# ioam3358 register map
Registers are 32-bit, access not given, no defined reset value unless marked. A register's access mark holds for its fields unless they carry their own. Addresses are absolute; registers are grouped by the start of their names; [hi:lo] are bit positions; {n}, {i} and the like mark numbered series; 'fields as' and 'values as' point back to an identical list.

## CM
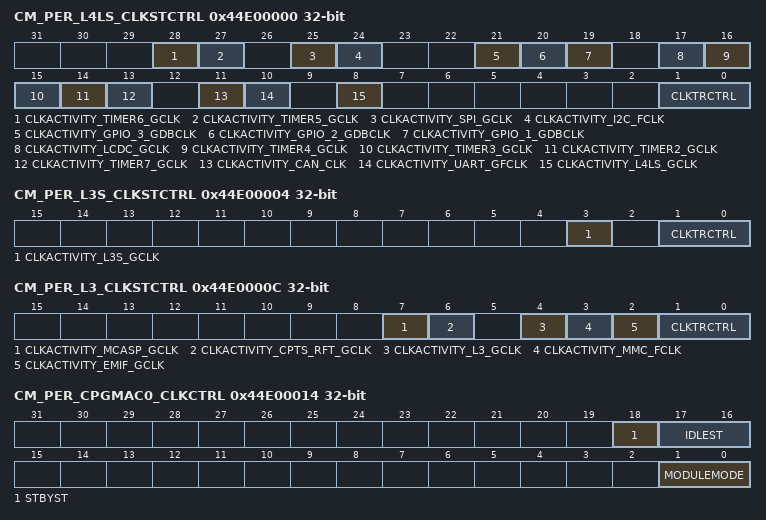
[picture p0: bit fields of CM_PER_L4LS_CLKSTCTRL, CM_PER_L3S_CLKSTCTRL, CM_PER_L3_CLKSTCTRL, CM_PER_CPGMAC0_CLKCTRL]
0x44E00000 CM_PER_L4LS_CLKSTCTRL
  [28] CLKACTIVITY_TIMER6_GCLK, [27] CLKACTIVITY_TIMER5_GCLK, [25] CLKACTIVITY_SPI_GCLK, [24] CLKACTIVITY_I2C_FCLK, [21] CLKACTIVITY_GPIO_3_GDBCLK, [20] CLKACTIVITY_GPIO_2_GDBCLK, [19] CLKACTIVITY_GPIO_1_GDBCLK, [17] CLKACTIVITY_LCDC_GCLK, [16] CLKACTIVITY_TIMER4_GCLK, [15] CLKACTIVITY_TIMER3_GCLK, [14] CLKACTIVITY_TIMER2_GCLK, [13] CLKACTIVITY_TIMER7_GCLK, [11] CLKACTIVITY_CAN_CLK, [10] CLKACTIVITY_UART_GFCLK, [8] CLKACTIVITY_L4LS_GCLK, [1:0] CLKTRCTRL
0x44E00004 CM_PER_L3S_CLKSTCTRL
  [3] CLKACTIVITY_L3S_GCLK, [1:0] CLKTRCTRL
0x44E0000C CM_PER_L3_CLKSTCTRL
  [7] CLKACTIVITY_MCASP_GCLK, [6] CLKACTIVITY_CPTS_RFT_GCLK, [4] CLKACTIVITY_L3_GCLK, [3] CLKACTIVITY_MMC_FCLK, [2] CLKACTIVITY_EMIF_GCLK, [1:0] CLKTRCTRL
0x44E00014 CM_PER_CPGMAC0_CLKCTRL
  [18] STBYST, [17:16] IDLEST, [1:0] MODULEMODE
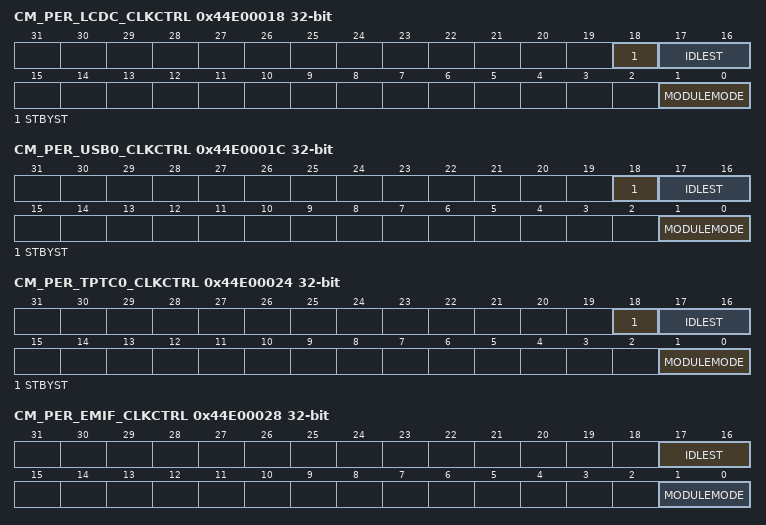
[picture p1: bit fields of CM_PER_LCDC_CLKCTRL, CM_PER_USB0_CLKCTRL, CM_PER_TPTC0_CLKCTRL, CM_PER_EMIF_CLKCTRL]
0x44E00018 CM_PER_LCDC_CLKCTRL
  [18] STBYST, [17:16] IDLEST, [1:0] MODULEMODE
0x44E0001C CM_PER_USB0_CLKCTRL
  [18] STBYST, [17:16] IDLEST, [1:0] MODULEMODE
0x44E00024 CM_PER_TPTC0_CLKCTRL
  [18] STBYST, [17:16] IDLEST, [1:0] MODULEMODE
0x44E00028 CM_PER_EMIF_CLKCTRL
  [17:16] IDLEST, [1:0] MODULEMODE
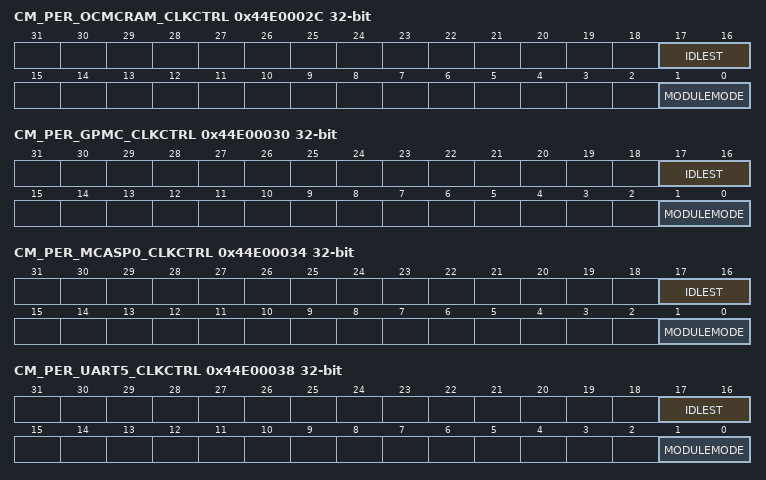
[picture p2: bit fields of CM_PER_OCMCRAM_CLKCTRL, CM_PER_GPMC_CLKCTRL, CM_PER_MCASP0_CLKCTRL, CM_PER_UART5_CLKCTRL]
0x44E0002C CM_PER_OCMCRAM_CLKCTRL
  [17:16] IDLEST, [1:0] MODULEMODE
0x44E00030 CM_PER_GPMC_CLKCTRL
  [17:16] IDLEST, [1:0] MODULEMODE
0x44E00034 CM_PER_MCASP0_CLKCTRL
  [17:16] IDLEST, [1:0] MODULEMODE
0x44E00038 CM_PER_UART5_CLKCTRL
  [17:16] IDLEST, [1:0] MODULEMODE
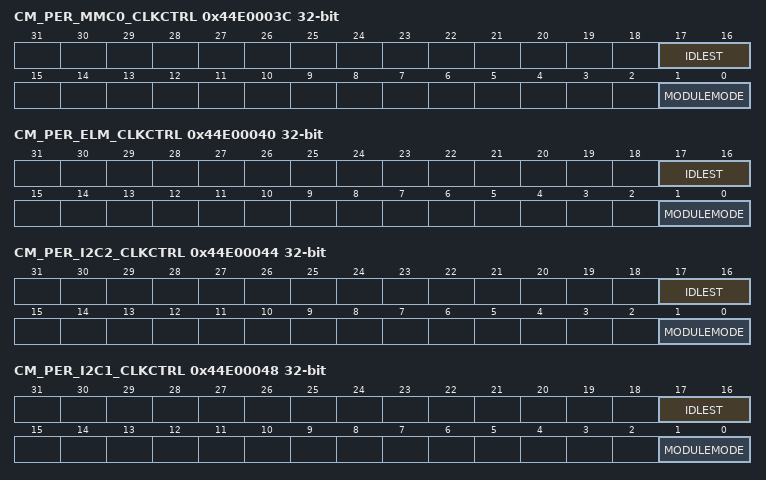
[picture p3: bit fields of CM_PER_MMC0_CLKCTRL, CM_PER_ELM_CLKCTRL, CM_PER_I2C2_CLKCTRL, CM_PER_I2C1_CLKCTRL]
0x44E0003C CM_PER_MMC0_CLKCTRL
  [17:16] IDLEST, [1:0] MODULEMODE
0x44E00040 CM_PER_ELM_CLKCTRL
  [17:16] IDLEST, [1:0] MODULEMODE
0x44E00044 CM_PER_I2C2_CLKCTRL
  [17:16] IDLEST, [1:0] MODULEMODE
0x44E00048 CM_PER_I2C1_CLKCTRL
  [17:16] IDLEST, [1:0] MODULEMODE
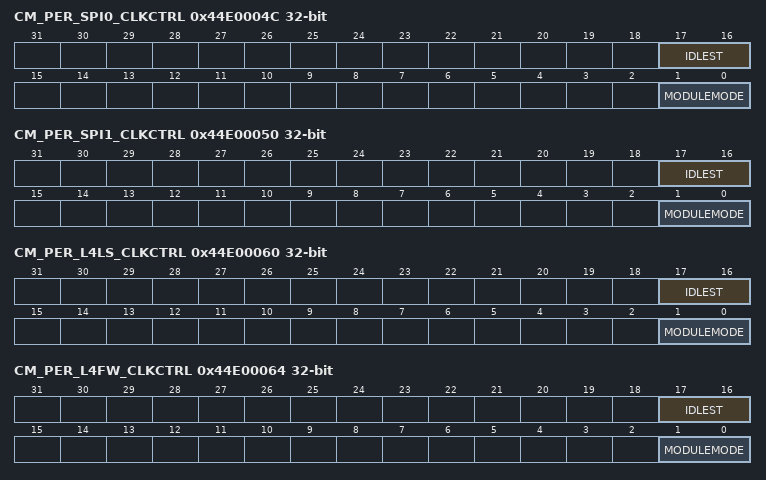
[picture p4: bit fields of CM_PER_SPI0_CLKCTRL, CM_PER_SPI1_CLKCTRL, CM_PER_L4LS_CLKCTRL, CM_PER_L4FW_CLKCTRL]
0x44E0004C CM_PER_SPI0_CLKCTRL
  [17:16] IDLEST, [1:0] MODULEMODE
0x44E00050 CM_PER_SPI1_CLKCTRL
  [17:16] IDLEST, [1:0] MODULEMODE
0x44E00060 CM_PER_L4LS_CLKCTRL
  [17:16] IDLEST, [1:0] MODULEMODE
0x44E00064 CM_PER_L4FW_CLKCTRL
  [17:16] IDLEST, [1:0] MODULEMODE
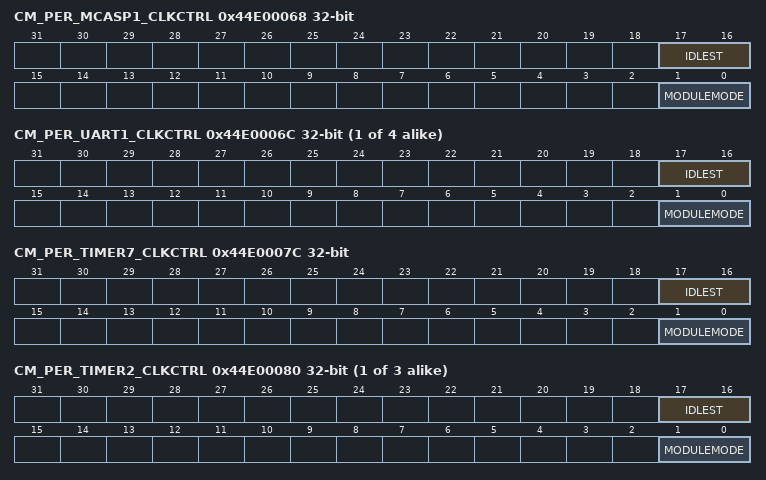
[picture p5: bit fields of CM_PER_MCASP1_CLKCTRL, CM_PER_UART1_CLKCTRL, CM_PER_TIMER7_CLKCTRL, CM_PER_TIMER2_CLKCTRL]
0x44E00068 CM_PER_MCASP1_CLKCTRL
  [17:16] IDLEST, [1:0] MODULEMODE
{0x44E00068+4i} CM_PER_UART{i}_CLKCTRL (i=1..4)
  [17:16] IDLEST, [1:0] MODULEMODE
0x44E0007C CM_PER_TIMER7_CLKCTRL
  [17:16] IDLEST, [1:0] MODULEMODE
{0x44E00078+4i} CM_PER_TIMER{i}_CLKCTRL (i=2..4)
  [17:16] IDLEST, [1:0] MODULEMODE
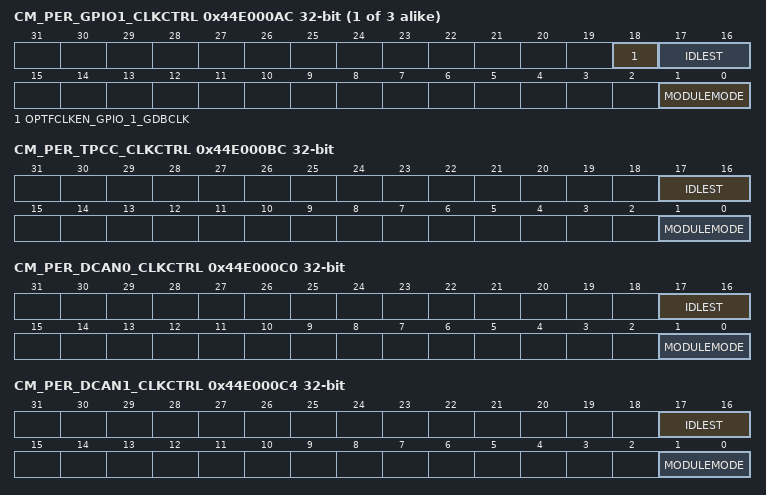
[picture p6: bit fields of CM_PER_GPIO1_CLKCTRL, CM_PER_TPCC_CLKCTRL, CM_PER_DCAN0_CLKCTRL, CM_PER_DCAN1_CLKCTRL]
{0x44E000A8+4i} CM_PER_GPIO{i}_CLKCTRL (i=1..3)
  [18] OPTFCLKEN_GPIO_{i}_GDBCLK, [17:16] IDLEST, [1:0] MODULEMODE
0x44E000BC CM_PER_TPCC_CLKCTRL
  [17:16] IDLEST, [1:0] MODULEMODE
0x44E000C0 CM_PER_DCAN0_CLKCTRL
  [17:16] IDLEST, [1:0] MODULEMODE
0x44E000C4 CM_PER_DCAN1_CLKCTRL
  [17:16] IDLEST, [1:0] MODULEMODE
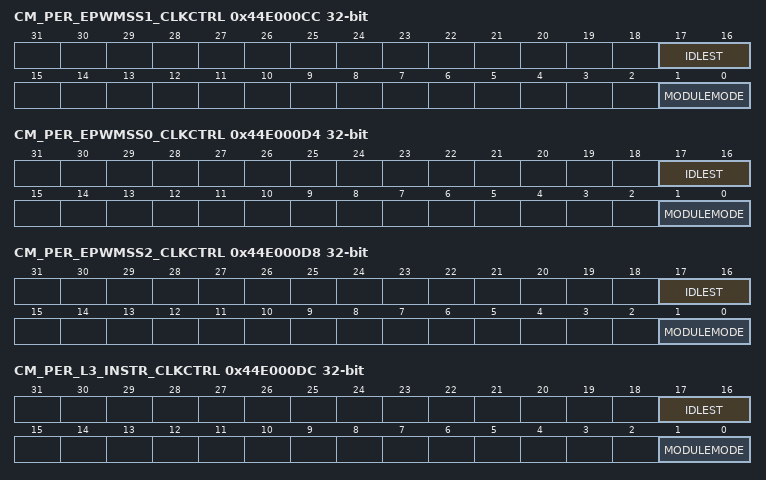
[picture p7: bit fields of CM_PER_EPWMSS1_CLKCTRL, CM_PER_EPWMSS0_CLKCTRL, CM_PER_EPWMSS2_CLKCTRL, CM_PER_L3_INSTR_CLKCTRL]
0x44E000CC CM_PER_EPWMSS1_CLKCTRL
  [17:16] IDLEST, [1:0] MODULEMODE
0x44E000D4 CM_PER_EPWMSS0_CLKCTRL
  [17:16] IDLEST, [1:0] MODULEMODE
0x44E000D8 CM_PER_EPWMSS2_CLKCTRL
  [17:16] IDLEST, [1:0] MODULEMODE
0x44E000DC CM_PER_L3_INSTR_CLKCTRL
  [17:16] IDLEST, [1:0] MODULEMODE
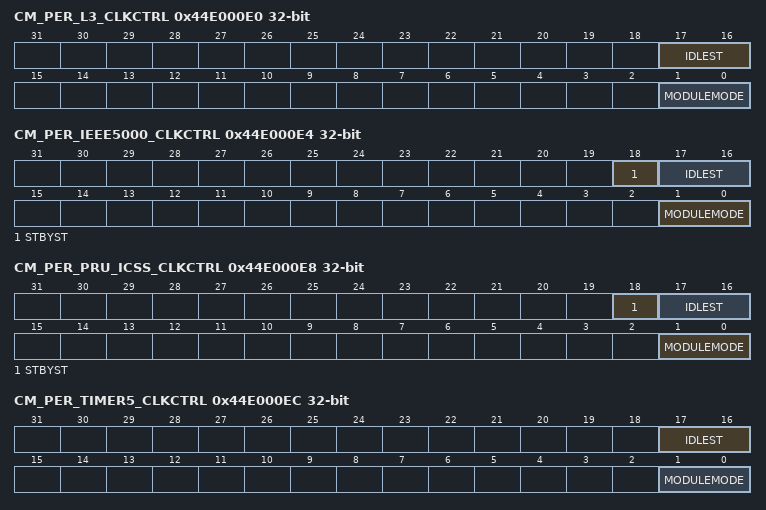
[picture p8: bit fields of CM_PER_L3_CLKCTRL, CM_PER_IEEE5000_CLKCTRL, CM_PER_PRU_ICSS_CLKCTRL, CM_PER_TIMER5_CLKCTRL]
0x44E000E0 CM_PER_L3_CLKCTRL
  [17:16] IDLEST, [1:0] MODULEMODE
0x44E000E4 CM_PER_IEEE5000_CLKCTRL
  [18] STBYST, [17:16] IDLEST, [1:0] MODULEMODE
0x44E000E8 CM_PER_PRU_ICSS_CLKCTRL
  [18] STBYST, [17:16] IDLEST, [1:0] MODULEMODE
0x44E000EC CM_PER_TIMER5_CLKCTRL
  [17:16] IDLEST, [1:0] MODULEMODE
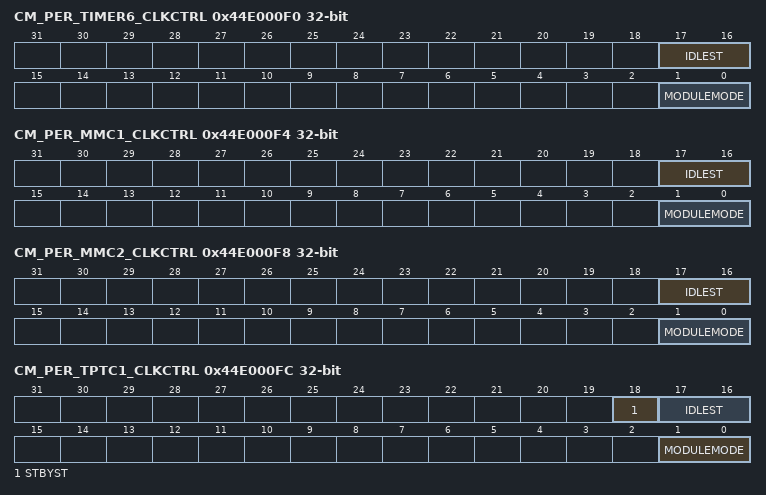
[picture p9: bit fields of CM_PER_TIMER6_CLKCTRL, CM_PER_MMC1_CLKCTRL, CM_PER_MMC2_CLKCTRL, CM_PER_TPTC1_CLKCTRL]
0x44E000F0 CM_PER_TIMER6_CLKCTRL
  [17:16] IDLEST, [1:0] MODULEMODE
0x44E000F4 CM_PER_MMC1_CLKCTRL
  [17:16] IDLEST, [1:0] MODULEMODE
0x44E000F8 CM_PER_MMC2_CLKCTRL
  [17:16] IDLEST, [1:0] MODULEMODE
0x44E000FC CM_PER_TPTC1_CLKCTRL
  [18] STBYST, [17:16] IDLEST, [1:0] MODULEMODE
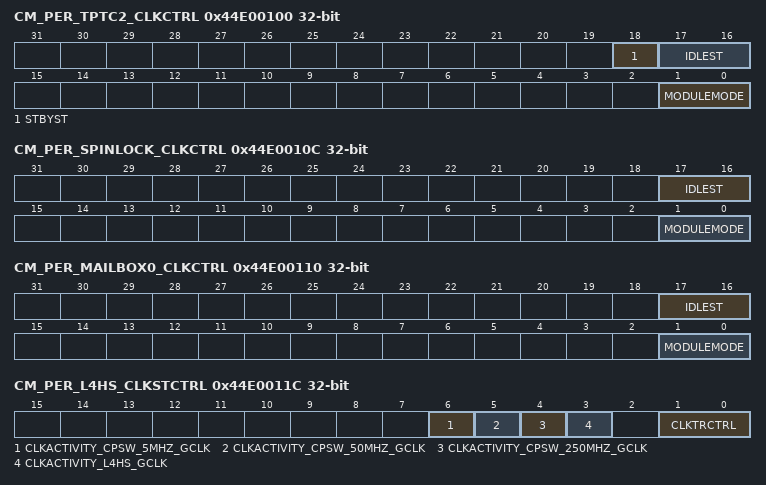
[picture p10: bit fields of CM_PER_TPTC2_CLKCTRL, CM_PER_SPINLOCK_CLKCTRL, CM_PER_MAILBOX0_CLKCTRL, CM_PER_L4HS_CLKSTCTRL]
0x44E00100 CM_PER_TPTC2_CLKCTRL
  [18] STBYST, [17:16] IDLEST, [1:0] MODULEMODE
0x44E0010C CM_PER_SPINLOCK_CLKCTRL
  [17:16] IDLEST, [1:0] MODULEMODE
0x44E00110 CM_PER_MAILBOX0_CLKCTRL
  [17:16] IDLEST, [1:0] MODULEMODE
0x44E0011C CM_PER_L4HS_CLKSTCTRL
  [6] CLKACTIVITY_CPSW_5MHZ_GCLK, [5] CLKACTIVITY_CPSW_50MHZ_GCLK, [4] CLKACTIVITY_CPSW_250MHZ_GCLK, [3] CLKACTIVITY_L4HS_GCLK, [1:0] CLKTRCTRL
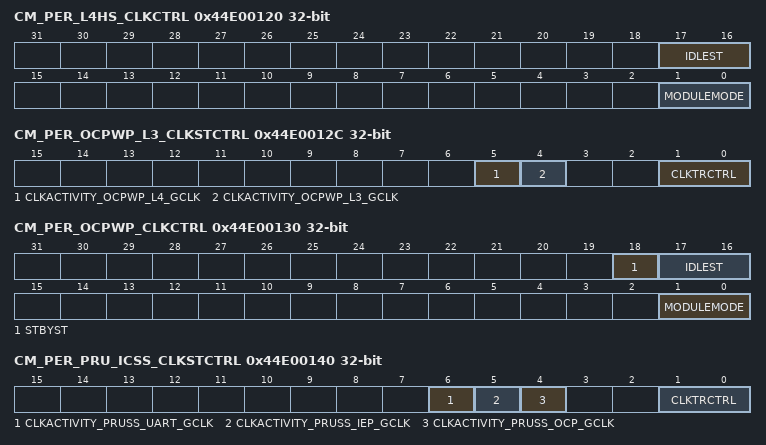
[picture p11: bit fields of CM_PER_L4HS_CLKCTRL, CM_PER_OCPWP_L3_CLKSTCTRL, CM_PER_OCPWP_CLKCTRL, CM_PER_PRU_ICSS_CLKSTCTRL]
0x44E00120 CM_PER_L4HS_CLKCTRL
  [17:16] IDLEST, [1:0] MODULEMODE
0x44E0012C CM_PER_OCPWP_L3_CLKSTCTRL
  [5] CLKACTIVITY_OCPWP_L4_GCLK, [4] CLKACTIVITY_OCPWP_L3_GCLK, [1:0] CLKTRCTRL
0x44E00130 CM_PER_OCPWP_CLKCTRL
  [18] STBYST, [17:16] IDLEST, [1:0] MODULEMODE
0x44E00140 CM_PER_PRU_ICSS_CLKSTCTRL
  [6] CLKACTIVITY_PRUSS_UART_GCLK, [5] CLKACTIVITY_PRUSS_IEP_GCLK, [4] CLKACTIVITY_PRUSS_OCP_GCLK, [1:0] CLKTRCTRL
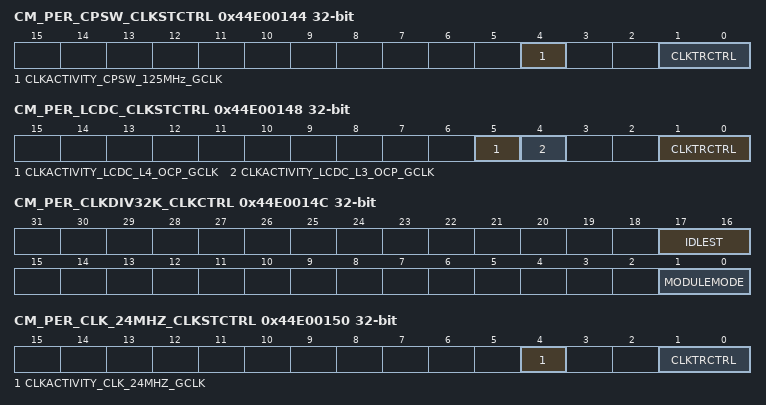
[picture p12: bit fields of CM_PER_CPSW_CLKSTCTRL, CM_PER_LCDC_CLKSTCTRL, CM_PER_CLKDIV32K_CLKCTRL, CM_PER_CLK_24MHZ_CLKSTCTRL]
0x44E00144 CM_PER_CPSW_CLKSTCTRL
  [4] CLKACTIVITY_CPSW_125MHz_GCLK, [1:0] CLKTRCTRL
0x44E00148 CM_PER_LCDC_CLKSTCTRL
  [5] CLKACTIVITY_LCDC_L4_OCP_GCLK, [4] CLKACTIVITY_LCDC_L3_OCP_GCLK, [1:0] CLKTRCTRL
0x44E0014C CM_PER_CLKDIV32K_CLKCTRL
  [17:16] IDLEST, [1:0] MODULEMODE
0x44E00150 CM_PER_CLK_24MHZ_CLKSTCTRL
  [4] CLKACTIVITY_CLK_24MHZ_GCLK, [1:0] CLKTRCTRL
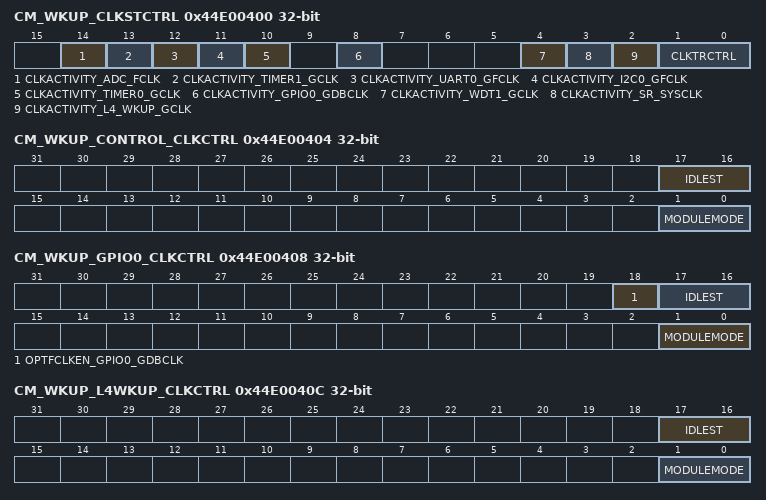
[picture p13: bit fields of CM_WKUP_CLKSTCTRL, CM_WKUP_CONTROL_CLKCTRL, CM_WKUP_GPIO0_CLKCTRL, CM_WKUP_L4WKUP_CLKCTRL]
0x44E00400 CM_WKUP_CLKSTCTRL
  [14] CLKACTIVITY_ADC_FCLK, [13] CLKACTIVITY_TIMER1_GCLK, [12] CLKACTIVITY_UART0_GFCLK, [11] CLKACTIVITY_I2C0_GFCLK, [10] CLKACTIVITY_TIMER0_GCLK, [8] CLKACTIVITY_GPIO0_GDBCLK, [4] CLKACTIVITY_WDT1_GCLK, [3] CLKACTIVITY_SR_SYSCLK, [2] CLKACTIVITY_L4_WKUP_GCLK, [1:0] CLKTRCTRL
0x44E00404 CM_WKUP_CONTROL_CLKCTRL
  [17:16] IDLEST, [1:0] MODULEMODE
0x44E00408 CM_WKUP_GPIO0_CLKCTRL
  [18] OPTFCLKEN_GPIO0_GDBCLK, [17:16] IDLEST, [1:0] MODULEMODE
0x44E0040C CM_WKUP_L4WKUP_CLKCTRL
  [17:16] IDLEST, [1:0] MODULEMODE
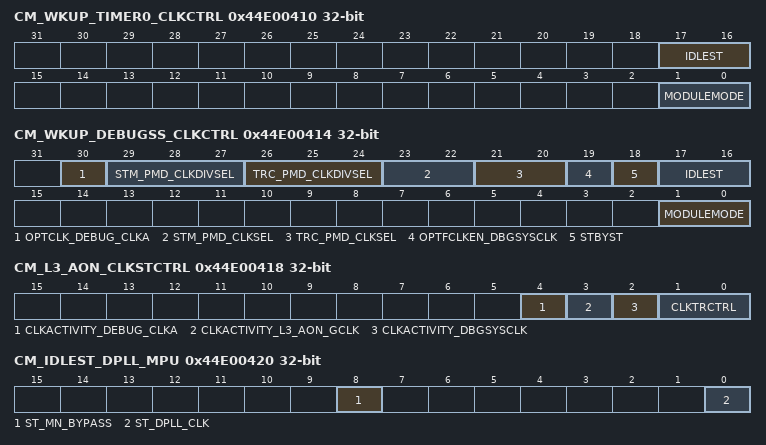
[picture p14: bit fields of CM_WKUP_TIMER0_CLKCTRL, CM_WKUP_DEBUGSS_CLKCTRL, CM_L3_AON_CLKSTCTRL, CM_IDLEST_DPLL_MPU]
0x44E00410 CM_WKUP_TIMER0_CLKCTRL
  [17:16] IDLEST, [1:0] MODULEMODE
0x44E00414 CM_WKUP_DEBUGSS_CLKCTRL
  [30] OPTCLK_DEBUG_CLKA, [29:27] STM_PMD_CLKDIVSEL, [26:24] TRC_PMD_CLKDIVSEL, [23:22] STM_PMD_CLKSEL, [21:20] TRC_PMD_CLKSEL, [19] OPTFCLKEN_DBGSYSCLK, [18] STBYST, [17:16] IDLEST, [1:0] MODULEMODE
0x44E00418 CM_L3_AON_CLKSTCTRL
  [4] CLKACTIVITY_DEBUG_CLKA, [3] CLKACTIVITY_L3_AON_GCLK, [2] CLKACTIVITY_DBGSYSCLK, [1:0] CLKTRCTRL
0x44E0041C CM_AUTOIDLE_DPLL_MPU
  [2:0] AUTO_DPLL_MODE
0x44E00420 CM_IDLEST_DPLL_MPU
  [8] ST_MN_BYPASS, [0] ST_DPLL_CLK
0x44E00424 CM_SSC_DELTAMSTEP_DPLL_MPU
  [19:0] DELTAMSTEP
0x44E00428 CM_SSC_MODFREQDIV_DPLL_MPU
  [10:8] MODFREQDIV_EXPONENT, [6:0] MODFREQDIV_MANTISSA
0x44E0042C CM_CLKSEL_DPLL_MPU
  [23] DPLL_BYP_CLKSEL, [18:8] DPLL_MULT, [6:0] DPLL_DIV
0x44E00430 CM_AUTOIDLE_DPLL_DDR
  [2:0] AUTO_DPLL_MODE
0x44E00434 CM_IDLEST_DPLL_DDR
  [8] ST_MN_BYPASS, [0] ST_DPLL_CLK
0x44E00438 CM_SSC_DELTAMSTEP_DPLL_DDR
  [19:0] DELTAMSTEP
0x44E0043C CM_SSC_MODFREQDIV_DPLL_DDR
  [10:8] MODFREQDIV_EXPONENT, [6:0] MODFREQDIV_MANTISSA
0x44E00440 CM_CLKSEL_DPLL_DDR
  [23] DPLL_BYP_CLKSEL, [18:8] DPLL_MULT, [6:0] DPLL_DIV
0x44E00444 CM_AUTOIDLE_DPLL_DISP
  [2:0] AUTO_DPLL_MODE
0x44E00448 CM_IDLEST_DPLL_DISP
  [8] ST_MN_BYPASS, [0] ST_DPLL_CLK
0x44E0044C CM_SSC_DELTAMSTEP_DPLL_DISP
  [19:0] DELTAMSTEP
0x44E00450 CM_SSC_MODFREQDIV_DPLL_DISP
  [10:8] MODFREQDIV_EXPONENT, [6:0] MODFREQDIV_MANTISSA
0x44E00454 CM_CLKSEL_DPLL_DISP
  [23] DPLL_BYP_CLKSEL, [18:8] DPLL_MULT, [6:0] DPLL_DIV
0x44E00458 CM_AUTOIDLE_DPLL_CORE
  [2:0] AUTO_DPLL_MODE
0x44E0045C CM_IDLEST_DPLL_CORE
  [8] ST_MN_BYPASS, [0] ST_DPLL_CLK
0x44E00460 CM_SSC_DELTAMSTEP_DPLL_CORE
  [19:0] DELTAMSTEP
0x44E00464 CM_SSC_MODFREQDIV_DPLL_CORE
  [10:8] MODFREQDIV_EXPONENT, [6:0] MODFREQDIV_MANTISSA
0x44E00468 CM_CLKSEL_DPLL_CORE
  [23] DPLL_BYP_CLKSEL, [18:8] DPLL_MULT, [6:0] DPLL_DIV
0x44E0046C CM_AUTOIDLE_DPLL_PER
  [2:0] AUTO_DPLL_MODE
0x44E00470 CM_IDLEST_DPLL_PER
  [8] ST_MN_BYPASS, [0] ST_DPLL_CLK
0x44E00474 CM_SSC_DELTAMSTEP_DPLL_PER
  [19:0] DELTAMSTEP
0x44E00478 CM_SSC_MODFREQDIV_DPLL_PER
  [10:8] MODFREQDIV_EXPONENT, [6:0] MODFREQDIV_MANTISSA
0x44E0047C CM_CLKDCOLDO_DPLL_PER
  [12] DPLL_CLKDCOLDO_PWDN, [9] ST_DPLL_CLKDCOLDO, [8] DPLL_CLKDCOLDO_GATE_CTRL
0x44E00480 CM_DIV_M4_DPLL_CORE
  [12] HSDIVIDER_CLKOUT1_PWDN, [9] ST_HSDIVIDER_CLKOUT1, [8] HSDIVIDER_CLKOUT1_GATE_CTRL, [5] HSDIVIDER_CLKOUT1_DIVCHACK, [4:0] HSDIVIDER_CLKOUT1_DIV
0x44E00484 CM_DIV_M5_DPLL_CORE
  [12] HSDIVIDER_CLKOUT2_PWDN, [9] ST_HSDIVIDER_CLKOUT2, [8] HSDIVIDER_CLKOUT2_GATE_CTRL, [5] HSDIVIDER_CLKOUT2_DIVCHACK, [4:0] HSDIVIDER_CLKOUT2_DIV
0x44E00488 CM_CLKMODE_DPLL_MPU
  [15] DPLL_SSC_TYPE, [14] DPLL_SSC_DOWNSPREAD, [13] DPLL_SSC_ACK, [12] DPLL_SSC_EN, [11] DPLL_REGM4XEN, [10] DPLL_LPMODE_EN, [9] DPLL_RELOCK_RAMP_EN, [8] DPLL_DRIFTGUARD_EN, [7:5] DPLL_RAMP_RATE, [4:3] DPLL_RAMP_LEVEL, [2:0] DPLL_EN
0x44E0048C CM_CLKMODE_DPLL_PER
  [15] DPLL_SSC_TYPE, [14] DPLL_SSC_DOWNSPREAD, [13] DPLL_SSC_ACK, [12] DPLL_SSC_EN, [2:0] DPLL_EN
0x44E00490 CM_CLKMODE_DPLL_CORE
  fields as CM_CLKMODE_DPLL_MPU
0x44E00494 CM_CLKMODE_DPLL_DDR
  fields as CM_CLKMODE_DPLL_MPU
0x44E00498 CM_CLKMODE_DPLL_DISP
  fields as CM_CLKMODE_DPLL_MPU
0x44E0049C CM_CLKSEL_DPLL_PERIPH
  [31:24] DPLL_SD_DIV, [19:8] DPLL_MULT, [7:0] DPLL_DIV
0x44E004A0 CM_DIV_M2_DPLL_DDR
  [9] ST_DPLL_CLKOUT, [8] DPLL_CLKOUT_GATE_CTRL, [5] DPLL_CLKOUT_DIVCHACK, [4:0] DPLL_CLKOUT_DIV
0x44E004A4 CM_DIV_M2_DPLL_DISP
  fields as CM_DIV_M2_DPLL_DDR
0x44E004A8 CM_DIV_M2_DPLL_MPU
  fields as CM_DIV_M2_DPLL_DDR
0x44E004AC CM_DIV_M2_DPLL_PER
  [9] ST_DPLL_CLKOUT, [8] DPLL_CLKOUT_GATE_CTRL, [7] DPLL_CLKOUT_DIVCHACK, [6:0] DPLL_CLKOUT_DIV
0x44E004B0 CM_WKUP_WKUP_M3_CLKCTRL
  [18] STBYST, [1:0] MODULEMODE
0x44E004B4 CM_WKUP_UART0_CLKCTRL
  [17:16] IDLEST, [1:0] MODULEMODE
0x44E004B8 CM_WKUP_I2C0_CLKCTRL
  [17:16] IDLEST, [1:0] MODULEMODE
0x44E004BC CM_WKUP_ADC_TSC_CLKCTRL
  [17:16] IDLEST, [1:0] MODULEMODE
0x44E004C0 CM_WKUP_SMARTREFLEX0_CLKCTRL
  [17:16] IDLEST, [1:0] MODULEMODE
0x44E004C4 CM_WKUP_TIMER1_CLKCTRL
  [17:16] IDLEST, [1:0] MODULEMODE
0x44E004C8 CM_WKUP_SMARTREFLEX1_CLKCTRL
  [17:16] IDLEST, [1:0] MODULEMODE
0x44E004CC CM_L4_WKUP_AON_CLKSTCTRL
  [2] CLKACTIVITY_L4_WKUP_AON_GCLK, [1:0] CLKTRCTRL
0x44E004D4 CM_WKUP_WDT1_CLKCTRL
  [17:16] IDLEST, [1:0] MODULEMODE
0x44E004D8 CM_DIV_M6_DPLL_CORE
  [12] HSDIVIDER_CLKOUT3_PWDN, [9] ST_HSDIVIDER_CLKOUT3, [8] HSDIVIDER_CLKOUT3_GATE_CTRL, [5] HSDIVIDER_CLKOUT3_DIVCHACK, [4:0] HSDIVIDER_CLKOUT3_DIV
0x44E00514 CM_MAC_CLKSEL
  [2] MII_CLK_SEL
0x44E00524 CM_CPTS_RFT_CLKSEL
  [0] CLKSEL
0x44E00600 CM_MPU_CLKSTCTRL
  [2] CLKACTIVITY_MPU_CLK, [1:0] CLKTRCTRL
0x44E00604 CM_MPU_MPU_CLKCTRL
  [18] STBYST, [17:16] IDLEST, [1:0] MODULEMODE
0x44E00700 CM_CLKOUT_CTRL
  [7] CLKOUT2EN, [5:3] CLKOUT2DIV, [2:0] CLKOUT2SOURCE
0x44E00800 CM_RTC_RTC_CLKCTRL
  [17:16] IDLEST, [1:0] MODULEMODE
0x44E00804 CM_RTC_CLKSTCTRL
  [9] CLKACTIVITY_RTC_32KCLK, [8] CLKACTIVITY_L4_RTC_GCLK, [1:0] CLKTRCTRL
0x44E00900 CM_GFX_L3_CLKSTCTRL
  [9] CLKACTIVITY_GFX_FCLK, [8] CLKACTIVITY_GFX_L3_GCLK, [1:0] CLKTRCTRL
0x44E00904 CM_GFX_GFX_CLKCTRL
  [18] STBYST, [17:16] IDLEST, [1:0] MODULEMODE
0x44E0090C CM_GFX_L4LS_GFX_CLKSTCTRL
  [8] CLKACTIVITY_GFX_FCLK, [1:0] CLKTRCTRL
0x44E00910 CM_GFX_MMUCFG_CLKCTRL
  [17:16] IDLEST, [1:0] MODULEMODE
0x44E00914 CM_GFX_MMUDATA_CLKCTRL
  [17:16] IDLEST, [1:0] MODULEMODE
0x44E00A00 CM_CEFUSE_CLKSTCTRL
  [9] CLKACTIVITY_CUST_EFUSE_SYS_CLK, [8] CLKACTIVITY_L4_CEFUSE_GICLK, [1:0] CLKTRCTRL
0x44E00A20 CM_CEFUSE_CEFUSE_CLKCTRL
  [17:16] IDLEST, [1:0] MODULEMODE
